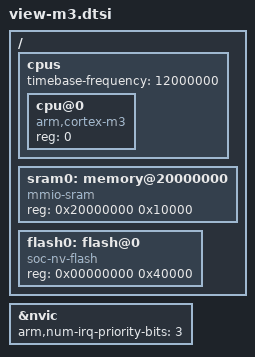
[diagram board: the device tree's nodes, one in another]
/* SPDX-License-Identifier: Apache-2.0 */

#include <arm/armv7-m.dtsi>

/ {
	cpus {
		#address-cells = <1>;
		#size-cells = <0>;
		timebase-frequency = <12000000>;

		cpu@0 {
			device_type = "cpu";
			compatible = "arm,cortex-m3";
			reg = <0>;
		};
	};

	sram0: memory@20000000 {
		compatible = "mmio-sram";
		reg = <0x20000000 0x10000>;
	};

	flash0: flash@0 {
		compatible = "soc-nv-flash";
		reg = <0x00000000 0x40000>;
	};
};

&nvic {
	arm,num-irq-priority-bits = <3>;
};
